# RSL15 register map
Vendor: ONSemiconductor; Series: RSL15 Series; File version: 1.0
CPU: CM33 r0p4, little endian, MPU, FPU, 3 interrupt priority bits
Registers are 32-bit, read-write, reset 0x0 unless marked. A register's access mark holds for its fields unless they carry their own. Offsets are from the block's base; [hi:lo] are bit positions; {n}, {i} and the like mark numbered series.

## FLASH — Flash Interface
Base 0x40000800
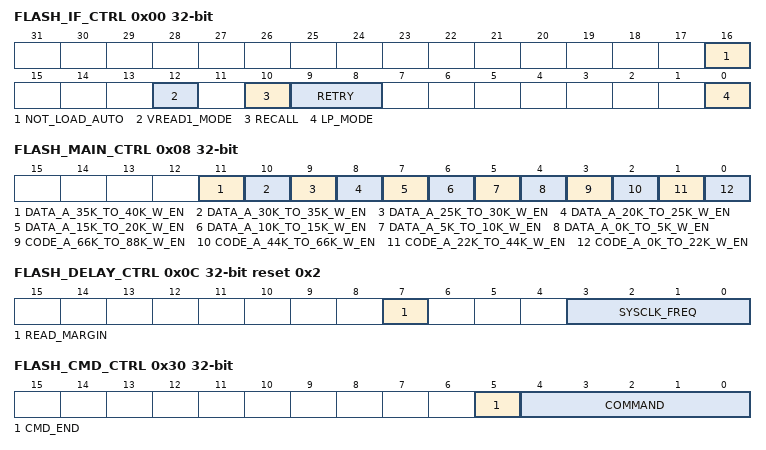
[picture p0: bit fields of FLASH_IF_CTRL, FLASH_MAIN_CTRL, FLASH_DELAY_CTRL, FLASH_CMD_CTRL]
0x00 FLASH_IF_CTRL — Flash Interface Control Register
  [16] NOT_LOAD_AUTO — Do not automatically load the configuration registers and the patch information from MNVR sector after the command WAKEUP is completed.
    0=FLASH_LOAD_AUTO_ENABLE (No automatic load done after the WAKEUP command); 1=FLASH_LOAD_AUTO_DISABLE (The CMD_WAKEUP includes the loading of internal registers and patch information.)
  [12] VREAD1_MODE — Control VREAD1: Read data after erase with more stringent condition than normal read. Changing this bit will execute the CMD_SET_VREAD1 or CMD_UNSET_VREAD1 command.
    0=FLASH_VREAD1_DISABLE (After erase, read data with a normal condition); 1=FLASH_VREAD1_ENABLE (After erase, read data with a more stringent condition)
  [10] RECALL — Set the recall pins mode during CMD_READ. Changing this bit will execute the CMD_SET_RECALL or CMD_UNSET_RECALL command.
    0=FLASH_RECALL_DISABLE (RECALL pin low during read command); 1=FLASH_RECALL_ENABLE (RECALL pin high during read command)
  [9:8] RETRY — Configures the erase retry iteration. This impacts the Flash endurance time. Also used by Flash programming.
    0=FLASH_RETRY_1 (for 1st erase pulse); 1=FLASH_RETRY_2 (for 2nd erase pulse); 2=FLASH_RETRY_3 (for 3rd erase pulse); 3=FLASH_RETRY_4 (for 4th erase pulse or required during programming)
  [0] LP_MODE — Set the low power mode. Changing this bit will execute the CMD_SET_LOW_POWER or CMD_UNSET_LOW_POWER command.
    0=FLASH_LOW_POWER_DISABLE (Disable the Flash low power mode); 1=FLASH_LOW_POWER_ENABLE (Enable the Flash low power mode)
0x04 FLASH_MAIN_WRITE_UNLOCK reset not defined
  [31:0] UNLOCK_KEY wo — 32-bit key to allow for write accesses into the Flash MAIN Block
    0xDBC8264E=FLASH_MAIN_KEY (32-bit key to allow for Read and Write accesses into the Flash MAIN Block)
0x08 FLASH_MAIN_CTRL — Flash Main Write Control Register
  [11] DATA_A_35K_TO_40K_W_EN — Authorize the write access to the Flash MAIN Data array from 35K to 40K word block through the FLASH_IF registers.
    0=DATA_A_35K_TO_40K_W_DISABLE (The part K to K of the Flash MAIN Data array is protected against write access); 1=DATA_A_35K_TO_40K_W_ENABLE (The part K to K of the Flash MAIN Data array can be written)
  [10] DATA_A_30K_TO_35K_W_EN — Authorize the write access to the Flash MAIN Data array from 30K to 35K word block through the FLASH_IF registers.
    0=DATA_A_30K_TO_35K_W_DISABLE (The part K to K of the Flash MAIN Data array is protected against write access); 1=DATA_A_30K_TO_35K_W_ENABLE (The part K to K of the Flash MAIN Data array can be written)
  [9] DATA_A_25K_TO_30K_W_EN — Authorize the write access to the Flash MAIN Data array from 25K to 30K word block through the FLASH_IF registers.
    0=DATA_A_25K_TO_30K_W_DISABLE (The part K to K of the Flash MAIN Data array is protected against write access); 1=DATA_A_25K_TO_30K_W_ENABLE (The part K to K of the Flash MAIN Data array can be written)
  [8] DATA_A_20K_TO_25K_W_EN — Authorize the write access to the Flash MAIN Data array from 20K to 25K word block through the FLASH_IF registers.
    0=DATA_A_20K_TO_25K_W_DISABLE (The part K to K of the Flash MAIN Data array is protected against write access); 1=DATA_A_20K_TO_25K_W_ENABLE (The part K to K of the Flash MAIN Data array can be written)
  [7] DATA_A_15K_TO_20K_W_EN — Authorize the write access to the Flash MAIN Data array from 15K to 20K word block through the FLASH_IF registers.
    0=DATA_A_15K_TO_20K_W_DISABLE (The part K to K of the Flash MAIN Data array is protected against write access); 1=DATA_A_15K_TO_20K_W_ENABLE (The part K to K of the Flash MAIN Data array can be written)
  [6] DATA_A_10K_TO_15K_W_EN — Authorize the write access to the Flash MAIN Data array from 10K to 15K word block through the FLASH_IF registers.
    0=DATA_A_10K_TO_15K_W_DISABLE (The part K to K of the Flash MAIN Data array is protected against write access); 1=DATA_A_10K_TO_15K_W_ENABLE (The part K to K of the Flash MAIN Data array can be written)
  [5] DATA_A_5K_TO_10K_W_EN — Authorize the write access to the Flash MAIN Data array from 5K to 10K word block through the FLASH_IF registers.
    0=DATA_A_5K_TO_10K_W_DISABLE (The part K to K of the Flash MAIN Data array is protected against write access); 1=DATA_A_5K_TO_10K_W_ENABLE (The part K to K of the Flash MAIN Data array can be written)
  [4] DATA_A_0K_TO_5K_W_EN — Authorize the write access to the Flash MAIN Data array from 0 to 5K word block through the FLASH_IF registers.
    0=DATA_A_0K_TO_5K_W_DISABLE (The part K to K of the Flash MAIN Data array is protected against write access); 1=DATA_A_0K_TO_5K_W_ENABLE (The part K to K of the Flash MAIN Data array can be written)
  [3] CODE_A_66K_TO_88K_W_EN — Authorize the write access to the Flash MAIN Code array from 66K to 88K word block through the FLASH_IF registers.
    0=CODE_A_66K_TO_88K_W_DISABLE (The part K to K of the Flash MAIN Code array is protected against write access); 1=CODE_A_66K_TO_88K_W_ENABLE (The part K to K of the Flash MAIN Code array can be written)
  [2] CODE_A_44K_TO_66K_W_EN — Authorize the write access to the Flash MAIN Code array from 44K to 66K word block through the FLASH_IF registers.
    0=CODE_A_44K_TO_66K_W_DISABLE (The part K to K of the Flash MAIN Code array is protected against write access); 1=CODE_A_44K_TO_66K_W_ENABLE (The part K to K of the Flash MAIN Code array can be written)
  [1] CODE_A_22K_TO_44K_W_EN — Authorize the write access to the Flash MAIN Code array from 22K to 44K word block through the FLASH_IF registers.
    0=CODE_A_22K_TO_44K_W_DISABLE (The part K to K of the Flash MAIN Code array is protected against write access); 1=CODE_A_22K_TO_44K_W_ENABLE (The part K to K of the Flash MAIN Code array can be written)
  [0] CODE_A_0K_TO_22K_W_EN — Authorize the write access to the Flash MAIN Code array from 0 to 22K word block through the FLASH_IF registers.
    0=CODE_A_0K_TO_22K_W_DISABLE (The part K to K of the Flash MAIN Code array is protected against write access); 1=CODE_A_0K_TO_22K_W_ENABLE (The part K to K of the Flash MAIN Code array can be written)
0x0C FLASH_DELAY_CTRL reset 0x2 — Flash, Memory and RF Power-Up Delay Configuration
  [7] READ_MARGIN — Flash Read access time margin
    0=DEFAULT_READ_MARGIN (Use default read margins); 1=FAST_READ_MARGIN (Use fast read margins)
  [3:0] SYSCLK_FREQ — Configure Flash, memory and RF power-up delays
    0=FLASH_DELAY_FOR_SYSCLK_3MHZ (FLASH_DELAY_CTRLx set for a SYSCLK = 3 MHz); 1=FLASH_DELAY_FOR_SYSCLK_4MHZ (FLASH_DELAY_CTRLx set for a SYSCLK = 4 MHz); 2=FLASH_DELAY_FOR_SYSCLK_5MHZ (FLASH_DELAY_CTRLx set for a SYSCLK = 5 MHz); 3=FLASH_DELAY_FOR_SYSCLK_8MHZ (FLASH_DELAY_CTRLx set for a SYSCLK = 8 MHz); 4=FLASH_DELAY_FOR_SYSCLK_10MHZ (FLASH_DELAY_CTRLx set for a SYSCLK = 10 MHz); 5=FLASH_DELAY_FOR_SYSCLK_12MHZ (FLASH_DELAY_CTRLx set for a SYSCLK = 12 MHz); 6=FLASH_DELAY_FOR_SYSCLK_16MHZ (FLASH_DELAY_CTRLx set for a SYSCLK = 16 MHz); 7=FLASH_DELAY_FOR_SYSCLK_20MHZ (FLASH_DELAY_CTRLx set for a SYSCLK = 20 MHz); 8=FLASH_DELAY_FOR_SYSCLK_24MHZ (FLASH_DELAY_CTRLx set for a SYSCLK = 24 MHz); 9=FLASH_DELAY_FOR_SYSCLK_48MHZ (FLASH_DELAY_CTRLx set for a SYSCLK = 48 MHz)
0x30 FLASH_CMD_CTRL (reset mask 0x11F) — Flash Command Control Register
  [5] CMD_END wo — Terminates an active Flash command if possible (e.g. sequential programming sequence)
    1=CMD_END (Terminates an active Flash command if possible)
  [4:0] COMMAND — Flash access command only writable when equal to CMD_IDLE
    0=CMD_IDLE (Idle command); 1=CMD_WAKE_UP (Wake up the Flash); 2=CMD_LOAD_TRIM (Load patch & trimming values from MNVR); 5=CMD_READ (Execute a read cycle); 6=CMD_PROGRAM_NOSEQ (Execute a non-sequential programming cycle); 7=CMD_PROGRAM_SEQ (Starts a sequential programming sequence); 8=CMD_SECTOR_ERASE (Execute a sector erase cycle); 9=CMD_MASS_ERASE (Execute a mass erase cycle); 10=CMD_SET_LOW_POWER (Wait time to set the LPWR pin); 11=CMD_UNSET_LOW_POWER (Wait time to unset the LPWR pin); 12=CMD_SET_RECALL (Wait time to set the RECALL pin); 13=CMD_UNSET_RECALL (Wait time to unset the RECALL pin); 14=CMD_SET_VREAD1 (Wait time to set the VREAD1 pin); 15=CMD_UNSET_VREAD1 (Wait time to unset the VREAD1 pin); 16=CMD_WRITE_USER_RED (Write FLASH_DATA to PATCH4 of M NVR, FLASH_DATA[1] indicates which redundancy sector, FLASH_DATA[0] the data to write); 17=CMD_PRE_PROGRAM_NOSEQ (Execute a non-sequential pre-programming cycle); 18=CMD_PRE_PROGRAM_SEQ (Starts a sequential pre-programming sequence)
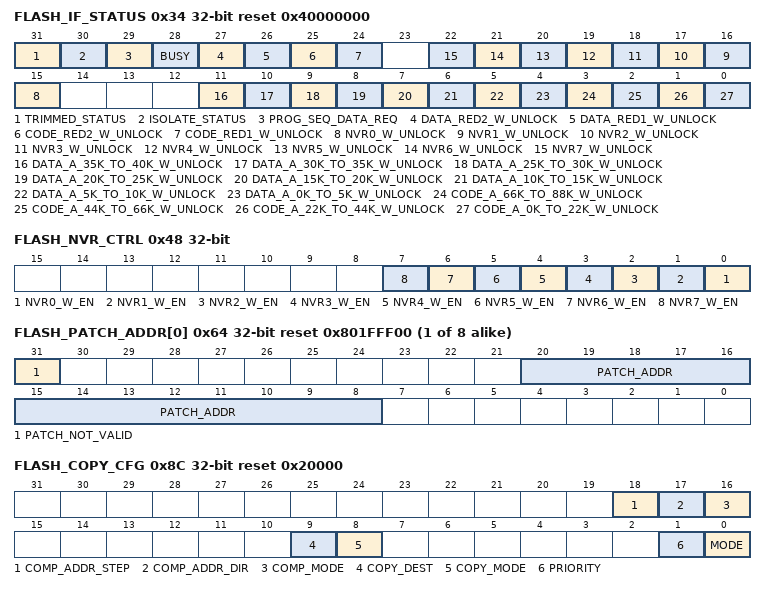
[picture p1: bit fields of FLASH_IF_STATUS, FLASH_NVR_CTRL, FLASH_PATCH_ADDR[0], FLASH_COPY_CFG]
0x34 FLASH_IF_STATUS ro reset 0x40000000 — Flash Interface Status Register
  [31] TRIMMED_STATUS — Flash trimming status
    0=FLASH_UNTRIMMED (All MNVR CBD0-CDB7 contents are equal to 0xFFFF. Flash untrimmed.); 1=FLASH_TRIMMED (Some registers CBD0-CBD7 contents are not equal to 0xFFFF. Flash trimmed.)
  [30] ISOLATE_STATUS — Flash isolate status
    0=FLASH_ACCESSIBLE (Flash can be accessed (isolation inactive)); 1=FLASH_ISOLATE (Flash cannot be accessed (isolation active))
  [29] PROG_SEQ_DATA_REQ — Request new data while in sequential program mode
    0=FLASH_PROG_SEQ_IDLE (No new data is requested by a Sequential Program sequence.); 1=FLASH_PROG_SEQ_REQ_NEW_DATA (New data is requested by a Sequential Program sequence.)
  [28] BUSY — Flash interface busy status bit
    0=FLASH_IF_IDLE (Indicates that the Flash interface is ready.); 1=FLASH_IF_BUSY (Indicates that the Flash interface is busy.)
  [27] DATA_RED2_W_UNLOCK — Flash Data array RED2 write unlock status bit
    0=FLASH_DATA_RED2_W_LOCKED (Indicates that the Flash Data array RED2 sector is protected against write accesses by the Flash interface); 1=FLASH_DATA_RED2_W_UNLOCKED (Indicates that the Flash Data array RED2 sector can be write accessed by the Flash interface)
  [26] DATA_RED1_W_UNLOCK — Flash Data array RED1 write unlock status bit
    0=FLASH_DATA_RED1_W_LOCKED (Indicates that the Flash Data array RED1 sector is protected against write accesses by the Flash interface); 1=FLASH_DATA_RED1_W_UNLOCKED (Indicates that the Flash Data array RED1 sector can be write accessed by the Flash interface)
  [25] CODE_RED2_W_UNLOCK — Flash Code array RED2 write unlock status bit
    0=FLASH_CODE_RED2_W_LOCKED (Indicates that the Flash Code array RED2 sector is protected against write accesses by the Flash interface); 1=FLASH_CODE_RED2_W_UNLOCKED (Indicates that the Flash Code array RED2 sector can be write accessed by the Flash interface)
  [24] CODE_RED1_W_UNLOCK — Flash Code array RED1 write unlock status bit
    0=FLASH_CODE_RED1_W_LOCKED (Indicates that the Flash Code array RED1 sector is protected against write accesses by the Flash interface); 1=FLASH_CODE_RED1_W_UNLOCKED (Indicates that the Flash Code array RED1 sector can be write accessed by the Flash interface)
  [n+15] NVR{n}_W_UNLOCK (n=0..7) — Flash NVR{n} write unlock status bit
    0=FLASH_NVR{n}_W_LOCKED (Indicates that the Flash NVR{n} sector is protected against write accesses by the Flash interface); 1=FLASH_NVR{n}_W_UNLOCKED (Indicates that the Flash NVR{n} sector can be write accessed by the Flash interface)
  [11] DATA_A_35K_TO_40K_W_UNLOCK — Write unlock status bit of the part 35K to 40K of the Flash MAIN Data array
    0=DATA_A_35K_TO_40K_W_LOCKED (Indicates that the part 35K to 40K of the Flash MAIN Data array is protected against write accesses by the Flash interface); 1=DATA_A_35K_TO_40K_W_UNLOCKED (Indicates that the part 35K to 40K of the Flash MAIN Data array can be write accessed by the Flash interface)
  [10] DATA_A_30K_TO_35K_W_UNLOCK — Write unlock status bit of the part 30K to 35K of the Flash MAIN Data array
    0=DATA_A_30K_TO_35K_W_LOCKED (Indicates that the part 30K to 35K of the Flash MAIN Data array is protected against write accesses by the Flash interface); 1=DATA_A_30K_TO_35K_W_UNLOCKED (Indicates that the part 30K to 35K of the Flash MAIN Data array can be write accessed by the Flash interface)
  [9] DATA_A_25K_TO_30K_W_UNLOCK — Write unlock status bit of the part 25K to 30K of the Flash MAIN Data array
    0=DATA_A_25K_TO_30K_W_LOCKED (Indicates that the part 25K to 30K of the Flash MAIN Data array is protected against write accesses by the Flash interface); 1=DATA_A_25K_TO_30K_W_UNLOCKED (Indicates that the part 25K to 30K of the Flash MAIN Data array can be write accessed by the Flash interface)
  [8] DATA_A_20K_TO_25K_W_UNLOCK — Write unlock status bit of the part 20K to 25K of the Flash MAIN Data array
    0=DATA_A_20K_TO_25K_W_LOCKED (Indicates that the part 20K to 25K of the Flash MAIN Data array is protected against write accesses by the Flash interface); 1=DATA_A_20K_TO_25K_W_UNLOCKED (Indicates that the part 20K to 25K of the Flash MAIN Data array can be write accessed by the Flash interface)
  [7] DATA_A_15K_TO_20K_W_UNLOCK — Write unlock status bit of the part 15K to 20K of the Flash MAIN Data array
    0=DATA_A_15K_TO_20K_W_LOCKED (Indicates that the part 15K to 20K of the Flash MAIN Data array is protected against write accesses by the Flash interface); 1=DATA_A_15K_TO_20K_W_UNLOCKED (Indicates that the part 15K to 20K of the Flash MAIN Data array can be write accessed by the Flash interface)
  [6] DATA_A_10K_TO_15K_W_UNLOCK — Write unlock status bit of the part 10K to 15K of the Flash MAIN Data array
    0=DATA_A_10K_TO_15K_W_LOCKED (Indicates that the part 10K to 15K of the Flash MAIN Data array is protected against write accesses by the Flash interface); 1=DATA_A_10K_TO_15K_W_UNLOCKED (Indicates that the part 10K to 15K of the Flash MAIN Data array can be write accessed by the Flash interface)
  [5] DATA_A_5K_TO_10K_W_UNLOCK — Write unlock status bit of the part 5K to 10K of the Flash MAIN Data array
    0=DATA_A_5K_TO_10K_W_LOCKED (Indicates that the part 5K to 10K of the Flash MAIN Data array is protected against write accesses by the Flash interface); 1=DATA_A_5K_TO_10K_W_UNLOCKED (Indicates that the part 5K to 10K of the Flash MAIN Data array can be write accessed by the Flash interface)
  [4] DATA_A_0K_TO_5K_W_UNLOCK — Write unlock status bit of the part 0K to 5K of the Flash MAIN Data array
    0=DATA_A_0K_TO_5K_W_LOCKED (Indicates that the part 0K to 5K of the Flash MAIN Data array is protected against write accesses by the Flash interface); 1=DATA_A_0K_TO_5K_W_UNLOCKED (Indicates that the part 0K to 5K of the Flash MAIN Data array can be write accessed by the Flash interface)
  [3] CODE_A_66K_TO_88K_W_UNLOCK — Write unlock status bit of the part 66K to 88K of the Flash MAIN Code array
    0=CODE_A_66K_TO_88K_W_LOCKED (Indicates that the part 66K to 88K of the Flash MAIN Code array is protected against write accesses by the Flash interface); 1=CODE_A_66K_TO_88K_W_UNLOCKED (Indicates that the part 66K to 88K of the Flash MAIN Code array can be write accessed by the Flash interface)
  [2] CODE_A_44K_TO_66K_W_UNLOCK — Write unlock status bit of the part 44K to 66K of the Flash MAIN Code array
    0=CODE_A_44K_TO_66K_W_LOCKED (Indicates that the part 44K to 66K of the Flash MAIN Code array is protected against write accesses by the Flash interface); 1=CODE_A_44K_TO_66K_W_UNLOCKED (Indicates that the part 44K to 66K of the Flash MAIN Code array can be write accessed by the Flash interface)
  [1] CODE_A_22K_TO_44K_W_UNLOCK — Write unlock status bit of the part 22K to 44K of the Flash MAIN Code array
    0=CODE_A_22K_TO_44K_W_LOCKED (Indicates that the part 22K to 44K of the Flash MAIN Code array is protected against write accesses by the Flash interface); 1=CODE_A_22K_TO_44K_W_UNLOCKED (Indicates that the part 22K to 44K of the Flash MAIN Code array can be write accessed by the Flash interface)
  [0] CODE_A_0K_TO_22K_W_UNLOCK — Write unlock status bit of the part 0K to 22K of the Flash MAIN Code array
    0=CODE_A_0K_TO_22K_W_LOCKED (Indicates that the part 0K to 22K of the Flash MAIN Code array is protected against write accesses by the Flash interface); 1=CODE_A_0K_TO_22K_W_UNLOCKED (Indicates that the part 0K to 22K of the Flash MAIN Code array can be write accessed by the Flash interface)
0x38 FLASH_ADDR — Flash Address Register
  [20:2] FLASH_ADDR — Flash Byte Address
{0x3C+4i} FLASH_DATA[{i}] (i=0..1) — Flash Read/Write Data Register
  [31:0] DATA — 32-bit Flash Data
0x44 FLASH_NVR_WRITE_UNLOCK reset not defined
  [31:0] UNLOCK_KEY wo — 32-bit key to allow for write access to NVR sectors of the Flash
    0x71B371F5=FLASH_NVR_KEY (32-bit key to allow for write access to the Flash NVR sector)
0x48 FLASH_NVR_CTRL — Flash NVR Control Register
  [n] NVR{n}_W_EN (n=0..7) — Authorize write access to the Flash NVR{n} sector through the FLASH_IF registers.
    0=NVR{n}_WRITE_DISABLE (The Flash NVR{n} block is protected against write access.); 1=NVR{n}_WRITE_ENABLE (The Flash NVR{n} block can be written.)
{0x64+4i} FLASH_PATCH_ADDR[{i}] (i=0..7) reset 0x801FFF00 — Flash Patch Address Register
  [31] PATCH_NOT_VALID — Indicates if the patch address is valid
    0=PATCH_VALID (This bit must be cleared in order for the patching to be taken into consideration.); 1=PATCH_NOT_VALID
  [20:8] PATCH_ADDR
0x8C FLASH_COPY_CFG reset 0x20000 — Flash Copier Config Register
  [18] COMP_ADDR_STEP — Comparator address increment/decrement by 1 or 2
    0=Address increment/decrement by 1 between two reads; 1=Address increment/decrement by 2 between two reads
  [17] COMP_ADDR_DIR — Comparator address-up or address-down
    0=COMP_ADDR_DOWN (FLASH_COPIER address count-down); 1=COMP_ADDR_UP (FLASH_COPIER address count-up)
  [16] COMP_MODE — Comparator Mode
    0=COMP_MODE_CONSTANT (FLASH_DATA[1:0] compare with Flash DOUT); 1=COMP_MODE_CHBK (Odd address compare with FLASH_DATA[1:0], even address compare with inverse FLASH_DATA[1:0])
  [9] COPY_DEST — Destination copier is the CRC or memories
    0=COPY_TO_MEM (Copy Flash to memory); 1=COPY_TO_CRC (Copy Flash to CRC)
  [8] COPY_MODE — Select copier mode (32-bit or 40-bit)
    0=COPY_TO_32BIT (Copy Flash to 32-bit memory)
  [1] PRIORITY — Copier Priority Configuration
    0=FLASH_CM33_PRIORITY (CM33 has priority over Flash Copier); 1=FLASH_COPY_PRIORITY (Flash Copier has priority over CM33)
  [0] MODE — Copier or Comparator Mode Configuration
    0=COPY_MODE (Flash copier mode); 1=COMPARATOR_MODE (Flash comparator mode)
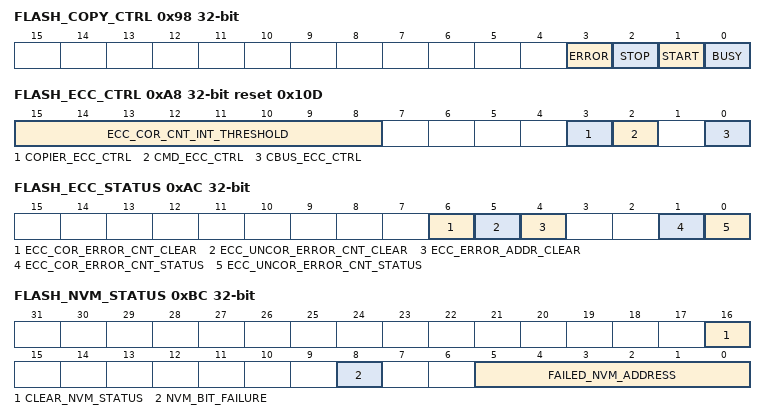
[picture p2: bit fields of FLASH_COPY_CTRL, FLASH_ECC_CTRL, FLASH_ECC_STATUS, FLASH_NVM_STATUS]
0x98 FLASH_COPY_CTRL (reset mask 0x9) — Flash Copier Control and Status
  [3] ERROR ro — Error status
    0=COPY_NO_ERROR (No write / comparison error); 1=COPY_ERROR (Write or comparison error)
  [2] STOP wo — Stop the transfer
    1=COPY_STOP (Stop the current transfer)
  [1] START wo — Start the transfer
    1=COPY_START (Start the current transfer)
  [0] BUSY ro — Busy status
    0=COPY_IDLE (Flash copier is idle); 1=COPY_BUSY (Flash copier is busy)
0x9C FLASH_COPY_SRC_ADDR_PTR — Flash Copier Source Address Pointer
  [20:0] COPY_SRC_ADDR_PTR — Source address pointer
0xA0 FLASH_COPY_DST_ADDR_PTR — Flash Copier Destination Address Pointer
  [31:2] COPY_DST_ADDR_PTR — Destination address pointer
0xA4 FLASH_COPY_WORD_CNT — Flash Copier Word Count
  [16:0] COPY_WORD_CNT — Number of words to copy / compare
0xA8 FLASH_ECC_CTRL reset 0x10D — Flash ECC Control Register
  [15:8] ECC_COR_CNT_INT_THRESHOLD — Select the number of corrected errors before sending a CM33 interrupt
    0=FLASH_ECC_COR_INT_THRESHOLD_DISABLED (Interrupt is disabled); 1=FLASH_ECC_COR_INT_THRESHOLD_1 (Send a CM33 interrupt when one or more correctable errors are detected.); 255=FLASH_ECC_COR_INT_THRESHOLD_255 (Send a CM33 interrupt when 255 or more correctable errors are detected.)
  [3] COPIER_ECC_CTRL
    0=FLASH_COPIER_ECC_DISABLE (Disables ECC when reading Flash through Flash Copier); 1=FLASH_COPIER_ECC_ENABLE (Enables ECC when reading Flash through Flash Copier)
  [2] CMD_ECC_CTRL
    0=FLASH_CMD_ECC_DISABLE (Disables ECC when reading Flash through Flash mapped register); 1=FLASH_CMD_ECC_ENABLE (Enables ECC when reading Flash through Flash mapped register)
  [0] CBUS_ECC_CTRL — Select the operating mode of the Flash ECC
    0=FLASH_CBUS_ECC_DISABLE (Disables ECC when reading Flash through CBus); 1=FLASH_CBUS_ECC_ENABLE (Enables ECC when reading Flash through CBus)
0xAC FLASH_ECC_STATUS (reset mask 0x3)
  [6] ECC_COR_ERROR_CNT_CLEAR wo — Reset the Flash corrected errors counter
    1=FLASH_ECC_COR_ERROR_CNT_CLEAR (Reset the Flash corrected errors counter)
  [5] ECC_UNCOR_ERROR_CNT_CLEAR wo — Reset the Flash uncorrected errors counter
    1=FLASH_ECC_UNCOR_ERROR_CNT_CLEAR (Reset the Flash uncorrected errors counter)
  [4] ECC_ERROR_ADDR_CLEAR wo — Reset the Flash address of the last detected error
    1=FLASH_ECC_ERROR_ADDR_CLEAR (Reset the Flash address of the latest detected error)
  [1] ECC_COR_ERROR_CNT_STATUS ro — FLASH_ECC_ERROR_COR_CNT status
    0=FLASH_ECC_NO_CORRECTED_ERROR (Indicates FLASH_ECC_COR_ERROR_CNT is zero); 1=FLASH_ECC_CORRECTED_ERROR (Indicates FLASH_ECC_COR_ERROR_CNT is not zero)
  [0] ECC_UNCOR_ERROR_CNT_STATUS ro — FLASH_ECC_ERROR_UNCOR_CNT status
    0=FLASH_ECC_NO_UNCORRECTED_ERROR (Indicates FLASH_ECC_UNCOR_ERROR_CNT is zero); 1=FLASH_ECC_UNCORRECTED_ERROR (Indicates FLASH_ECC_UNCOR_ERROR_CNT is not zero)
0xB0 FLASH_ECC_ERROR_ADDR ro — Flash Address of the Latest Detected Error
  [20:2] ECC_ERROR_ADDR — Store the Flash address of the latest Flash ECC error
0xB4 FLASH_ECC_UNCOR_ERROR_CNT ro — Flash ECC Uncorrected Error Counter
  [7:0] ECC_UNCOR_ERROR_CNT — Flash ECC uncorrected error counter
0xB8 FLASH_ECC_COR_ERROR_CNT ro — Flash ECC Corrected Error Counter
  [7:0] ECC_COR_ERROR_CNT — Flash ECC corrected error counter
0xBC FLASH_NVM_STATUS (reset mask 0x13F) — Flash NVM Status (only available when NVR_FOR_CC312 in ID_NUM register is 1)
  [16] CLEAR_NVM_STATUS wo — Clear all the NVM status bits
    1=CLEAR_NVM_STATUS (Clear all the NVM status bits)
  [8] NVM_BIT_FAILURE ro — Indicates if a bit has failed in an address from the CC-NVM layout used by the CryptoCell
    0=NVM_OK (No bit failure detection in the CC-NVM layout); 1=NVM_BIT_FAILED (At least a bit has failed in the CC-NVM layout)
  [5:0] FAILED_NVM_ADDRESS ro — Last failing word address in CC-NVM layout (0x00 to 0x3F)
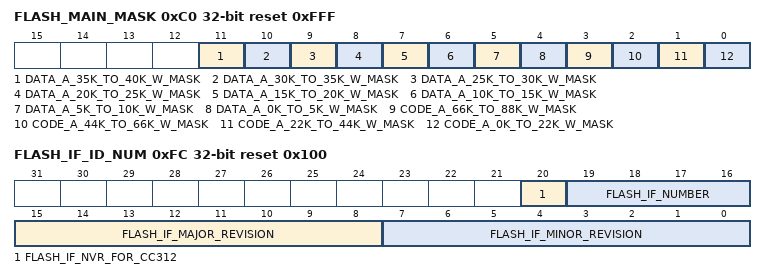
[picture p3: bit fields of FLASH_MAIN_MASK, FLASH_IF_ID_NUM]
0xC0 FLASH_MAIN_MASK ro reset 0xFFF
  [11] DATA_A_35K_TO_40K_W_MASK — Authorize the access to the Flash MAIN Data array from 35K to 40K word block through the FLASH_IF registers.
    0=DATA_A_35K_TO_40K_W_NOT_ACCESSIBLE (The part K to K of the Flash MAIN Data array is not accessible.); 1=DATA_A_35K_TO_40K_W_ACCESSIBLE (The part K to K of the Flash MAIN Data array is accessible.)
  [10] DATA_A_30K_TO_35K_W_MASK — Authorize the access to the Flash MAIN Data array from 30K to 35K word block through the FLASH_IF registers.
    0=DATA_A_30K_TO_35K_W_NOT_ACCESSIBLE (The part K to K of the Flash MAIN Data array is not accessible.); 1=DATA_A_30K_TO_35K_W_ACCESSIBLE (The part K to K of the Flash MAIN Data array is accessible.)
  [9] DATA_A_25K_TO_30K_W_MASK — Authorize the access to the Flash MAIN Data array from 25K to 30K word block through the FLASH_IF registers.
    0=DATA_A_25K_TO_30K_W_NOT_ACCESSIBLE (The part K to K of the Flash MAIN Data array is not accessible.); 1=DATA_A_25K_TO_30K_W_ACCESSIBLE (The part K to K of the Flash MAIN Data array is accessible.)
  [8] DATA_A_20K_TO_25K_W_MASK — Authorize the access to the Flash MAIN Data array from 20K to 25K word block through the FLASH_IF registers.
    0=DATA_A_20K_TO_25K_W_NOT_ACCESSIBLE (The part K to K of the Flash MAIN Data array is not accessible.); 1=DATA_A_20K_TO_25K_W_ACCESSIBLE (The part K to K of the Flash MAIN Data array is accessible.)
  [7] DATA_A_15K_TO_20K_W_MASK — Authorize the access to the Flash MAIN Data array from 15K to 20K word block through the FLASH_IF registers.
    0=DATA_A_15K_TO_20K_W_NOT_ACCESSIBLE (The part K to K of the Flash MAIN Data array is not accessible.); 1=DATA_A_15K_TO_20K_W_ACCESSIBLE (The part K to K of the Flash MAIN Data array is accessible.)
  [6] DATA_A_10K_TO_15K_W_MASK — Authorize the access to the Flash MAIN Data array from 10K to 15K word block through the FLASH_IF registers.
    0=DATA_A_10K_TO_15K_W_NOT_ACCESSIBLE (The part K to K of the Flash MAIN Data array is not accessible.); 1=DATA_A_10K_TO_15K_W_ACCESSIBLE (The part K to K of the Flash MAIN Data array is accessible.)
  [5] DATA_A_5K_TO_10K_W_MASK — Authorize the access to the Flash MAIN Data array from 5K to 10K word block through the FLASH_IF registers.
    0=DATA_A_5K_TO_10K_W_NOT_ACCESSIBLE (The part K to K of the Flash MAIN Data array is not accessible.); 1=DATA_A_5K_TO_10K_W_ACCESSIBLE (The part K to K of the Flash MAIN Data array is accessible.)
  [4] DATA_A_0K_TO_5K_W_MASK — Authorize the access to the Flash MAIN Data array from 0 to 5K word block through the FLASH_IF registers.
    0=DATA_A_0K_TO_5K_W_NOT_ACCESSIBLE (The part K to K of the Flash MAIN Data array is not accessible.); 1=DATA_A_0K_TO_5K_W_ACCESSIBLE (The part K to K of the Flash MAIN Data array is accessible.)
  [3] CODE_A_66K_TO_88K_W_MASK — Authorize the access to the Flash MAIN Code array from 66K to 88K word block through the FLASH_IF registers.
    0=CODE_A_66K_TO_88K_W_NOT_ACCESSIBLE (The part K to K of the Flash MAIN Code array is not accessible.); 1=CODE_A_66K_TO_88K_W_ACCESSIBLE (The part K to K of the Flash MAIN Code array is accessible.)
  [2] CODE_A_44K_TO_66K_W_MASK — Authorize the access to the Flash MAIN Code array from 44K to 66K word block through the FLASH_IF registers.
    0=CODE_A_44K_TO_66K_W_NOT_ACCESSIBLE (The part K to K of the Flash MAIN Code array is not accessible.); 1=CODE_A_44K_TO_66K_W_ACCESSIBLE (The part K to K of the Flash MAIN Code array is accessible.)
  [1] CODE_A_22K_TO_44K_W_MASK — Authorize the access to the Flash MAIN Code array from 22K to 44K word block through the FLASH_IF registers.
    0=CODE_A_22K_TO_44K_W_NOT_ACCESSIBLE (The part K to K of the Flash MAIN Code array is not accessible.); 1=CODE_A_22K_TO_44K_W_ACCESSIBLE (The part K to K of the Flash MAIN Code array is accessible.)
  [0] CODE_A_0K_TO_22K_W_MASK — Authorize the access to the Flash MAIN Code array from 0 to 22K word block through the FLASH_IF registers.
    0=CODE_A_0K_TO_22K_W_NOT_ACCESSIBLE (The part K to K of the Flash MAIN Code array is not accessible.); 1=CODE_A_0K_TO_22K_W_ACCESSIBLE (The part K to K of the Flash MAIN Code array is accessible.)
0xFC FLASH_IF_ID_NUM ro reset 0x100 — Flash Interface ID number
  [20] FLASH_IF_NVR_FOR_CC312 — NVR sectors 0 to 3 are used for the CryptoCell
    0=NVR_SECTORS_AVAILABLE (NVR sectors 0 to 3 are available to the user); 1=NVR_SECTORS_USED_BY_CRYPTOCELL (NVR sectors 0 to 3 are used by the CryptoCell and are not available to the user)
  [19:16] FLASH_IF_NUMBER — FLASH_IF Instance number
  [15:8] FLASH_IF_MAJOR_REVISION — FLASH_IF Major Revision number
    1=FLASH_IF_MAJOR_REVISION (Flash interface revision 1.0)
  [7:0] FLASH_IF_MINOR_REVISION — FLASH_IF Minor Revision number
    0=FLASH_IF_MINOR_REVISION (Flash interface revision 1.0)
